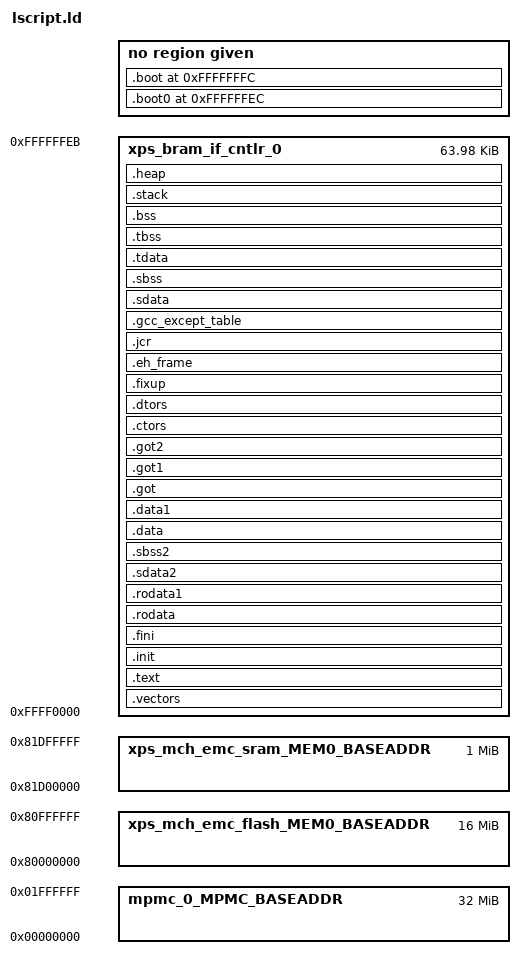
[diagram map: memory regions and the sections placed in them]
/*******************************************************************/
/*                                                                 */
/* This file is automatically generated by linker script generator.*/
/*                                                                 */
/* Version: Xilinx EDK 13.3 EDK_O.76xd                                */
/*                                                                 */
/* Copyright (c) 2010 Xilinx, Inc.  All rights reserved.           */
/*                                                                 */
/* Description : PowerPC405 Linker Script                          */
/*                                                                 */
/*******************************************************************/

_STACK_SIZE = DEFINED(_STACK_SIZE) ? _STACK_SIZE : 0x1000;
_HEAP_SIZE = DEFINED(_HEAP_SIZE) ? _HEAP_SIZE : 0x1000;
/* Define Memories in the system */

MEMORY
{
   xps_bram_if_cntlr_0 : ORIGIN = 0xFFFF0000, LENGTH = 0x0000FFEC
   xps_mch_emc_flash_MEM0_BASEADDR : ORIGIN = 0x80000000, LENGTH = 0x01000000
   xps_mch_emc_sram_MEM0_BASEADDR : ORIGIN = 0x81D00000, LENGTH = 0x00100000
   mpmc_0_MPMC_BASEADDR : ORIGIN = 0x00000000, LENGTH = 0x02000000
}

/* Specify the default entry point to the program */

ENTRY(_boot)
STARTUP(boot.o)

/* Define the sections, and where they are mapped in memory */

SECTIONS
{
.vectors : {
   __vectors_start = .;
   *(.vectors)
   __vectors_end = .;
} > xps_bram_if_cntlr_0

.text : {
   *(.text)
   *(.text.*)
   *(.gnu.linkonce.t.*)
} > xps_bram_if_cntlr_0

.init : {
   KEEP (*(.init))
} > xps_bram_if_cntlr_0

.fini : {
   KEEP (*(.fini))
} > xps_bram_if_cntlr_0

.rodata : {
   __rodata_start = .;
   *(.rodata)
   *(.rodata.*)
   *(.gnu.linkonce.r.*)
   __rodata_end = .;
} > xps_bram_if_cntlr_0

.rodata1 : {
   __rodata1_start = .;
   *(.rodata1)
   *(.rodata1.*)
   __rodata1_end = .;
} > xps_bram_if_cntlr_0

.sdata2 : {
   __sdata2_start = .;
   *(.sdata2)
   *(.sdata2.*)
   *(.gnu.linkonce.s2.*)
   __sdata2_end = .;
} > xps_bram_if_cntlr_0

.sbss2 : {
   __sbss2_start = .;
   *(.sbss2)
   *(.sbss2.*)
   *(.gnu.linkonce.sb2.*)
   __sbss2_end = .;
} > xps_bram_if_cntlr_0

.data : {
   __data_start = .;
   *(.data)
   *(.data.*)
   *(.gnu.linkonce.d.*)
   __data_end = .;
} > xps_bram_if_cntlr_0

.data1 : {
   __data1_start = .;
   *(.data1)
   *(.data1.*)
   __data1_end = .;
} > xps_bram_if_cntlr_0

.got : {
   *(.got)
} > xps_bram_if_cntlr_0

.got1 : {
   *(.got1)
} > xps_bram_if_cntlr_0

.got2 : {
   *(.got2)
} > xps_bram_if_cntlr_0

.ctors : {
   __CTOR_LIST__ = .;
   ___CTORS_LIST___ = .;
   KEEP (*crtbegin.o(.ctors))
   KEEP (*(EXCLUDE_FILE(*crtend.o) .ctors))
   KEEP (*(SORT(.ctors.*)))
   KEEP (*(.ctors))
   __CTOR_END__ = .;
   ___CTORS_END___ = .;
} > xps_bram_if_cntlr_0

.dtors : {
   __DTOR_LIST__ = .;
   ___DTORS_LIST___ = .;
   KEEP (*crtbegin.o(.dtors))
   KEEP (*(EXCLUDE_FILE(*crtend.o) .dtors))
   KEEP (*(SORT(.dtors.*)))
   KEEP (*(.dtors))
   __DTOR_END__ = .;
   ___DTORS_END___ = .;
} > xps_bram_if_cntlr_0

.fixup : {
   __fixup_start = .;
   *(.fixup)
   __fixup_end = .;
} > xps_bram_if_cntlr_0

.eh_frame : {
   *(.eh_frame)
} > xps_bram_if_cntlr_0

.jcr : {
   *(.jcr)
} > xps_bram_if_cntlr_0

.gcc_except_table : {
   *(.gcc_except_table)
} > xps_bram_if_cntlr_0

.sdata : {
   __sdata_start = .;
   *(.sdata)
   *(.sdata.*)
   *(.gnu.linkonce.s.*)
   __sdata_end = .;
} > xps_bram_if_cntlr_0

.sbss : {
   . = ALIGN(4);
   __sbss_start = .;
   *(.sbss)
   *(.sbss.*)
   *(.gnu.linkonce.sb.*)
   *(.scommon)
   . = ALIGN(4);
   __sbss_end = .;
} > xps_bram_if_cntlr_0

.tdata : {
   __tdata_start = .;
   *(.tdata)
   *(.tdata.*)
   *(.gnu.linkonce.td.*)
   __tdata_end = .;
} > xps_bram_if_cntlr_0

.tbss : {
   __tbss_start = .;
   *(.tbss)
   *(.tbss.*)
   *(.gnu.linkonce.tb.*)
   __tbss_end = .;
} > xps_bram_if_cntlr_0

.bss : {
   . = ALIGN(4);
   __bss_start = .;
   *(.bss)
   *(.bss.*)
   *(.gnu.linkonce.b.*)
   *(COMMON)
   . = ALIGN(4);
   __bss_end = .;
} > xps_bram_if_cntlr_0

.boot0 0xFFFFFFEC : {
   __boot0_start = .;
   *(.boot0)
   __boot0_end = .;
} 

.boot 0xFFFFFFFC : {
   __boot_start = .;
   *(.boot)
   __boot_end = .;
} 

/* Generate Stack and Heap Sections */

.stack : {
   _stack_end = .;
   . += _STACK_SIZE;
   . = ALIGN(16);
   __stack = .;
} > xps_bram_if_cntlr_0

.heap : {
   . = ALIGN(16);
   _heap_start = .;
   . += _HEAP_SIZE;
   . = ALIGN(16);
   _heap_end = .;
   _end = .;
} > xps_bram_if_cntlr_0

}

